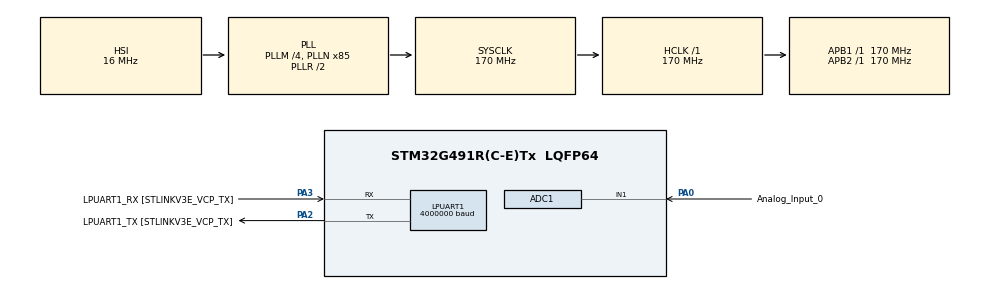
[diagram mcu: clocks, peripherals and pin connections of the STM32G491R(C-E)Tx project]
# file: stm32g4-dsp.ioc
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ADC1.Channel-0\#ChannelRegularConversion=ADC_CHANNEL_1
ADC1.ClockPrescaler=ADC_CLOCK_ASYNC_DIV8
ADC1.DMAContinuousRequests=ENABLE
ADC1.ExternalTrigConv=ADC_EXTERNALTRIG_T2_TRGO
ADC1.NbrOfConversionFlag=1
ADC1.OffsetNumber-0\#ChannelRegularConversion=ADC_OFFSET_NONE
ADC1.Rank-0\#ChannelRegularConversion=1
ADC1.SamplingTime-0\#ChannelRegularConversion=ADC_SAMPLETIME_2CYCLES_5
ADC1.master=1
Dma.ADC1.1.Direction=DMA_PERIPH_TO_MEMORY
Dma.ADC1.1.EventEnable=DISABLE
Dma.ADC1.1.Instance=DMA1_Channel2
Dma.ADC1.1.MemDataAlignment=DMA_MDATAALIGN_HALFWORD
Dma.ADC1.1.MemInc=DMA_MINC_ENABLE
Dma.ADC1.1.Mode=DMA_CIRCULAR
Dma.ADC1.1.PeriphDataAlignment=DMA_PDATAALIGN_HALFWORD
Dma.ADC1.1.PeriphInc=DMA_PINC_DISABLE
Dma.ADC1.1.Polarity=HAL_DMAMUX_REQ_GEN_RISING
Dma.ADC1.1.Priority=DMA_PRIORITY_MEDIUM
Dma.ADC1.1.RequestNumber=1
Dma.ADC1.1.SignalID=NONE
Dma.ADC1.1.SyncEnable=DISABLE
Dma.ADC1.1.SyncPolarity=HAL_DMAMUX_SYNC_NO_EVENT
Dma.ADC1.1.SyncRequestNumber=1
Dma.ADC1.1.SyncSignalID=NONE
Dma.LPUART1_TX.0.Direction=DMA_MEMORY_TO_PERIPH
Dma.LPUART1_TX.0.EventEnable=DISABLE
Dma.LPUART1_TX.0.Instance=DMA1_Channel1
Dma.LPUART1_TX.0.MemDataAlignment=DMA_MDATAALIGN_BYTE
Dma.LPUART1_TX.0.MemInc=DMA_MINC_ENABLE
Dma.LPUART1_TX.0.Mode=DMA_NORMAL
Dma.LPUART1_TX.0.PeriphDataAlignment=DMA_PDATAALIGN_BYTE
Dma.LPUART1_TX.0.PeriphInc=DMA_PINC_DISABLE
Dma.LPUART1_TX.0.Polarity=HAL_DMAMUX_REQ_GEN_RISING
Dma.LPUART1_TX.0.Priority=DMA_PRIORITY_MEDIUM
Dma.LPUART1_TX.0.RequestNumber=1
Dma.LPUART1_TX.0.SignalID=NONE
Dma.LPUART1_TX.0.SyncEnable=DISABLE
Dma.LPUART1_TX.0.SyncPolarity=HAL_DMAMUX_SYNC_NO_EVENT
Dma.LPUART1_TX.0.SyncRequestNumber=1
Dma.LPUART1_TX.0.SyncSignalID=NONE
Dma.Request0=LPUART1_TX
Dma.Request1=ADC1
FREERTOS.Tasks01=defaultTask,24,512,StartDefaultTask,Default,NULL,Dynamic,NULL,NULL
FREERTOS.configENABLE_FPU=1
FREERTOS.configMINIMAL_STACK_SIZE=512
FREERTOS.configTOTAL_HEAP_SIZE=32768
LPUART1.BaudRate=4000000
Mcu.Family=STM32G4
Mcu.Name=STM32G491R(C-E)Tx
Mcu.Package=LQFP64
NVIC.DMA1_Channel1_IRQn=true\:5\:0\:false\:false\:true\:true\:false\:true\:true
NVIC.DMA1_Channel2_IRQn=true\:5\:0\:false\:false\:true\:true\:false\:true\:true
NVIC.LPUART1_IRQn=true\:5\:0\:false\:false\:true\:true\:true\:true\:true
NVIC.PriorityGroup=NVIC_PRIORITYGROUP_4
NVIC.TIM1_UP_TIM16_IRQn=true\:15\:0\:false\:false\:true\:false\:false\:true\:true
NVIC.TimeBase=TIM1_UP_TIM16_IRQn
NVIC.TimeBaseIP=TIM1
PA0.GPIO_Label=Analog_Input_0
PA0.Signal=SharedAnalog_PA0
PA13.GPIO_Label=T_SWDIO
PA13.Signal=SYS_JTMS-SWDIO
PA14.GPIO_Label=T_SWCLK
PA14.Signal=SYS_JTCK-SWCLK
PA2.GPIO_Label=LPUART1_TX [STLINKV3E_VCP_TX]
PA2.Mode=Asynchronous
PA2.Signal=LPUART1_TX
PA3.GPIO_Label=LPUART1_RX [STLINKV3E_VCP_TX]
PA3.Mode=Asynchronous
PA3.Signal=LPUART1_RX
PB3.GPIO_Label=T_SWO
PB3.Signal=SYS_JTDO-SWO
PC14-OSC32_IN.GPIO_Label=RCC_OSC32_IN
PC14-OSC32_IN.Signal=RCC_OSC32_IN
PC15-OSC32_OUT.GPIO_Label=RCC_OSC32_OUT
PC15-OSC32_OUT.Signal=RCC_OSC32_OUT
PF0-OSC_IN.GPIO_Label=RCC_OSC_IN
PF0-OSC_IN.Signal=RCC_OSC_IN
PF1-OSC_OUT.GPIO_Label=RCC_OSC_OUT
PF1-OSC_OUT.Signal=RCC_OSC_OUT
ProjectManager.HeapSize=0x200
ProjectManager.StackSize=0x400
ProjectManager.TargetToolchain=CMake
RCC.ADC12Freq_Value=170000000
RCC.ADC345Freq_Value=170000000
RCC.AHBFreq_Value=170000000
RCC.APB1Freq_Value=170000000
RCC.APB1TimFreq_Value=170000000
RCC.APB2Freq_Value=170000000
RCC.APB2TimFreq_Value=170000000
RCC.CortexFreq_Value=170000000
RCC.EXTERNAL_CLOCK_VALUE=12288000
RCC.HCLKFreq_Value=170000000
RCC.HSE_VALUE=24000000
RCC.HSI48_VALUE=48000000
RCC.HSI_VALUE=16000000
RCC.LSE_VALUE=32768
RCC.PLLM=RCC_PLLM_DIV4
RCC.PLLN=85
RCC.RTCClockSelection=RCC_RTCCLKSOURCE_LSE
RCC.SYSCLKFreq_VALUE=170000000
RCC.SYSCLKSource=RCC_SYSCLKSOURCE_PLLCLK
RCC.USBFreq_Value=48000000
RCC.VCOOutputFreq_Value=340000000
SH.SharedAnalog_PA0.0=GPIO_Analog
SH.SharedAnalog_PA0.1=ADC1_IN1,IN1-Single-Ended
STMicroelectronics.X-CUBE-ALGOBUILD.1.4.0.LibraryCcDSPOoLibraryJjDSPOoLibrary=true
TIM2.Channel-Output\ Compare1\ No\ Output=TIM_CHANNEL_1
TIM2.PeriodNoDither=99
TIM2.Prescaler=169
TIM2.TIM_MasterOutputTrigger=TIM_TRGO_UPDATE
VP_FREERTOS_VS_CMSIS_V2.Mode=CMSIS_V2
VP_STMicroelectronics.X-CUBE-ALGOBUILD_VS_DSPOoLibraryJjLibrary_1.4.0_1.4.0.Mode=DSPOoLibraryJjLibrary
VP_SYS_VS_DBSignals.Mode=DisableDeadBatterySignals
VP_SYS_VS_tim1.Mode=TIM1
VP_TIM2_VS_no_output1.Mode=Output Compare1 No Output
board=NUCLEO-G491RE

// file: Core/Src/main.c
/* USER CODE BEGIN Header */
/**
  ******************************************************************************
  * @file           : main.c
  * @brief          : Main program body
  ******************************************************************************
  * @attention
  *
  * Copyright (c) 2025 STMicroelectronics.
  * All rights reserved.
  *
  * This software is licensed under terms that can be found in the LICENSE file
  * in the root directory of this software component.
  * If no LICENSE file comes with this software, it is provided AS-IS.
  *
  ******************************************************************************
  */
/* USER CODE END Header */
#include "main.h"
#include "cmsis_os.h"
#include "adc.h"
#include "dma.h"
#include "usart.h"
#include "tim.h"
#include "gpio.h"

void SystemClock_Config(void);
void MX_FREERTOS_Init(void);

int main(void)
{

  /* MCU Configuration--------------------------------------------------------*/

  /* Reset of all peripherals, Initializes the Flash interface and the Systick. */
  HAL_Init();

  /* Configure the system clock */
  SystemClock_Config();

  /* Initialize all configured peripherals */
  MX_GPIO_Init();
  MX_DMA_Init();
  MX_LPUART1_UART_Init();
  MX_ADC1_Init();
  MX_TIM2_Init();

  /* Init scheduler */
  osKernelInitialize();  /* Call init function for freertos objects (in cmsis_os2.c) */
  MX_FREERTOS_Init();

  /* Start scheduler */
  osKernelStart();

  /* We should never get here as control is now taken by the scheduler */

  /* Infinite loop */
  while (1)
  {

  }
}

void SystemClock_Config(void)
{
  RCC_OscInitTypeDef RCC_OscInitStruct = {0};
  RCC_ClkInitTypeDef RCC_ClkInitStruct = {0};

  /** Configure the main internal regulator output voltage
  */
  HAL_PWREx_ControlVoltageScaling(PWR_REGULATOR_VOLTAGE_SCALE1_BOOST);

  /** Initializes the RCC Oscillators according to the specified parameters
  * in the RCC_OscInitTypeDef structure.
  */
  RCC_OscInitStruct.OscillatorType = RCC_OSCILLATORTYPE_HSI;
  RCC_OscInitStruct.HSIState = RCC_HSI_ON;
  RCC_OscInitStruct.HSICalibrationValue = RCC_HSICALIBRATION_DEFAULT;
  RCC_OscInitStruct.PLL.PLLState = RCC_PLL_ON;
  RCC_OscInitStruct.PLL.PLLSource = RCC_PLLSOURCE_HSI;
  RCC_OscInitStruct.PLL.PLLM = RCC_PLLM_DIV4;
  RCC_OscInitStruct.PLL.PLLN = 85;
  RCC_OscInitStruct.PLL.PLLP = RCC_PLLP_DIV2;
  RCC_OscInitStruct.PLL.PLLQ = RCC_PLLQ_DIV2;
  RCC_OscInitStruct.PLL.PLLR = RCC_PLLR_DIV2;
  if (HAL_RCC_OscConfig(&RCC_OscInitStruct) != HAL_OK)
  {
    Error_Handler();
  }

  /** Initializes the CPU, AHB and APB buses clocks
  */
  RCC_ClkInitStruct.ClockType = RCC_CLOCKTYPE_HCLK|RCC_CLOCKTYPE_SYSCLK
                              |RCC_CLOCKTYPE_PCLK1|RCC_CLOCKTYPE_PCLK2;
  RCC_ClkInitStruct.SYSCLKSource = RCC_SYSCLKSOURCE_PLLCLK;
  RCC_ClkInitStruct.AHBCLKDivider = RCC_SYSCLK_DIV1;
  RCC_ClkInitStruct.APB1CLKDivider = RCC_HCLK_DIV1;
  RCC_ClkInitStruct.APB2CLKDivider = RCC_HCLK_DIV1;

  if (HAL_RCC_ClockConfig(&RCC_ClkInitStruct, FLASH_LATENCY_4) != HAL_OK)
  {
    Error_Handler();
  }
}

void HAL_TIM_PeriodElapsedCallback(TIM_HandleTypeDef *htim)
{
  if (htim->Instance == TIM1)
  {
    HAL_IncTick();
  }
}

void Error_Handler(void)
{
  __disable_irq();
  while (1)
  {
  }
}

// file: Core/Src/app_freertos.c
/* USER CODE BEGIN Header */
/**
  ******************************************************************************
  * File Name          : app_freertos.c
  * Description        : Code for freertos applications
  ******************************************************************************
  * @attention
  *
  * Copyright (c) 2025 STMicroelectronics.
  * All rights reserved.
  *
  * This software is licensed under terms that can be found in the LICENSE file
  * in the root directory of this software component.
  * If no LICENSE file comes with this software, it is provided AS-IS.
  *
  ******************************************************************************
  */
/* USER CODE END Header */

#include "FreeRTOS.h"
#include "task.h"
#include "main.h"
#include "cmsis_os.h"

/* USER CODE BEGIN Includes */
#include "driver.h"
/* USER CODE END Includes */

/* USER CODE BEGIN Variables */
AppContext app_context;
/* USER CODE END Variables */
/* Definitions for defaultTask */
osThreadId_t defaultTaskHandle;
const osThreadAttr_t defaultTask_attributes = {
  .name = "defaultTask",
  .priority = (osPriority_t) osPriorityNormal,
  .stack_size = 512 * 4
};

void StartDefaultTask(void *argument);

void MX_FREERTOS_Init(void); /* (MISRA C 2004 rule 8.1) */

void MX_FREERTOS_Init(void) {
  /* USER CODE BEGIN Init */
  Driver_Init(&app_context);
  /* USER CODE END Init */

  /* Create the thread(s) */
  /* creation of defaultTask */
  defaultTaskHandle = osThreadNew(StartDefaultTask, NULL, &defaultTask_attributes);

}

void StartDefaultTask(void *argument)
{
  /* USER CODE BEGIN StartDefaultTask */
  Driver_StartTasks(&app_context);

  // Kill Default Task
  vTaskDelete(NULL);

  /* Infinite loop */
  for(;;)
  {
    osDelay(1000);
  }
  /* USER CODE END StartDefaultTask */
}
